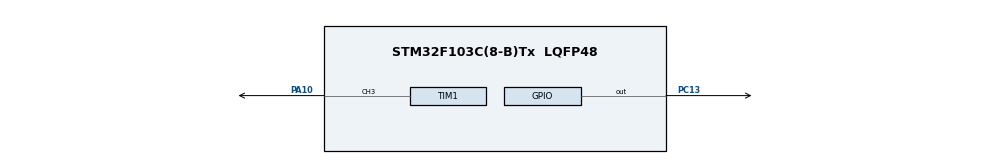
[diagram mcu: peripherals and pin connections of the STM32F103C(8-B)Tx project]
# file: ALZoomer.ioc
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Mcu.Family=STM32F1
Mcu.Name=STM32F103C(8-B)Tx
Mcu.Package=LQFP48
NVIC.PriorityGroup=NVIC_PRIORITYGROUP_4
PA10.Signal=S_TIM1_CH3
PA13.Mode=Serial_Wire
PA13.Signal=SYS_JTMS-SWDIO
PA14.Mode=Serial_Wire
PA14.Signal=SYS_JTCK-SWCLK
PC13-TAMPER-RTC.Signal=GPIO_Output
ProjectManager.HeapSize=0x200
ProjectManager.StackSize=0x400
ProjectManager.TargetToolchain=STM32CubeIDE
RCC.APB1Freq_Value=8000000
RCC.APB2Freq_Value=8000000
SH.S_TIM1_CH3.0=TIM1_CH3,PWM Generation3 CH3
TIM1.Channel-PWM\ Generation3\ CH3=TIM_CHANNEL_3
TIM1.Period=99
TIM1.Prescaler=39
TIM1.Pulse-PWM\ Generation3\ CH3=49
TIM1.RepetitionCounter=0
VP_TIM1_VS_ClockSourceINT.Mode=Internal
board=custom

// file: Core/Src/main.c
/* USER CODE BEGIN Header */
/**
  ******************************************************************************
  * @file           : main.c
  * @brief          : Main program body
  ******************************************************************************
  * @attention
  *
  * <h2><center>&copy; Copyright (c) 2021 STMicroelectronics.
  * All rights reserved.</center></h2>
  *
  * This software component is licensed by ST under BSD 3-Clause license,
  * the "License"; You may not use this file except in compliance with the
  * License. You may obtain a copy of the License at:
  *                        opensource.org/licenses/BSD-3-Clause
  *
  ******************************************************************************
  */
/* USER CODE END Header */

#include "main.h"

TIM_HandleTypeDef htim1;

void SystemClock_Config(void);
static void MX_GPIO_Init(void);
static void MX_TIM1_Init(void);
/* USER CODE BEGIN PFP */
void setPWM(uint16_t pwm_value);
/* USER CODE END PFP */

int main(void)
{

  /* MCU Configuration--------------------------------------------------------*/

  /* Reset of all peripherals, Initializes the Flash interface and the Systick. */
  HAL_Init();

  /* Configure the system clock */
  SystemClock_Config();

  /* Initialize all configured peripherals */
  MX_GPIO_Init();
  MX_TIM1_Init();

  /* Infinite loop */
  /* USER CODE BEGIN WHILE */
  while (1)
  {
//    setPWM(30);
    __HAL_TIM_SET_PRESCALER(&htim1, 39);
    HAL_TIM_PWM_Start(&htim1, TIM_CHANNEL_3);
    HAL_GPIO_WritePin(GPIOC, GPIO_PIN_13, GPIO_PIN_RESET);
    HAL_Delay(1000);
//    setPWM(0);
    HAL_TIM_PWM_Stop(&htim1, TIM_CHANNEL_3);
    HAL_GPIO_WritePin(GPIOC, GPIO_PIN_13, GPIO_PIN_SET);
    HAL_Delay(500);

    __HAL_TIM_SET_PRESCALER(&htim1, 29);
    HAL_TIM_PWM_Start(&htim1, TIM_CHANNEL_3);
    HAL_GPIO_WritePin(GPIOC, GPIO_PIN_13, GPIO_PIN_RESET);
    HAL_Delay(1000);
//    setPWM(0);
    HAL_TIM_PWM_Stop(&htim1, TIM_CHANNEL_3);
    HAL_GPIO_WritePin(GPIOC, GPIO_PIN_13, GPIO_PIN_SET);
    HAL_Delay(500);

    /* USER CODE END WHILE */

  }
}

void SystemClock_Config(void)
{
  RCC_OscInitTypeDef RCC_OscInitStruct = {0};
  RCC_ClkInitTypeDef RCC_ClkInitStruct = {0};

  /** Initializes the CPU, AHB and APB busses clocks
  */
  RCC_OscInitStruct.OscillatorType = RCC_OSCILLATORTYPE_HSI;
  RCC_OscInitStruct.HSIState = RCC_HSI_ON;
  RCC_OscInitStruct.HSICalibrationValue = RCC_HSICALIBRATION_DEFAULT;
  RCC_OscInitStruct.PLL.PLLState = RCC_PLL_NONE;
  if (HAL_RCC_OscConfig(&RCC_OscInitStruct) != HAL_OK)
  {
    Error_Handler();
  }
  /** Initializes the CPU, AHB and APB busses clocks
  */
  RCC_ClkInitStruct.ClockType = RCC_CLOCKTYPE_HCLK|RCC_CLOCKTYPE_SYSCLK
                              |RCC_CLOCKTYPE_PCLK1|RCC_CLOCKTYPE_PCLK2;
  RCC_ClkInitStruct.SYSCLKSource = RCC_SYSCLKSOURCE_HSI;
  RCC_ClkInitStruct.AHBCLKDivider = RCC_SYSCLK_DIV1;
  RCC_ClkInitStruct.APB1CLKDivider = RCC_HCLK_DIV1;
  RCC_ClkInitStruct.APB2CLKDivider = RCC_HCLK_DIV1;

  if (HAL_RCC_ClockConfig(&RCC_ClkInitStruct, FLASH_LATENCY_0) != HAL_OK)
  {
    Error_Handler();
  }
}

static void MX_TIM1_Init(void)
{

  TIM_ClockConfigTypeDef sClockSourceConfig = {0};
  TIM_MasterConfigTypeDef sMasterConfig = {0};
  TIM_OC_InitTypeDef sConfigOC = {0};
  TIM_BreakDeadTimeConfigTypeDef sBreakDeadTimeConfig = {0};

  htim1.Instance = TIM1;
  htim1.Init.Prescaler = 39;
  htim1.Init.CounterMode = TIM_COUNTERMODE_UP;
  htim1.Init.Period = 99;
  htim1.Init.ClockDivision = TIM_CLOCKDIVISION_DIV1;
  htim1.Init.RepetitionCounter = 0;
  htim1.Init.AutoReloadPreload = TIM_AUTORELOAD_PRELOAD_DISABLE;
  if (HAL_TIM_Base_Init(&htim1) != HAL_OK)
  {
    Error_Handler();
  }
  sClockSourceConfig.ClockSource = TIM_CLOCKSOURCE_INTERNAL;
  if (HAL_TIM_ConfigClockSource(&htim1, &sClockSourceConfig) != HAL_OK)
  {
    Error_Handler();
  }
  if (HAL_TIM_PWM_Init(&htim1) != HAL_OK)
  {
    Error_Handler();
  }
  sMasterConfig.MasterOutputTrigger = TIM_TRGO_RESET;
  sMasterConfig.MasterSlaveMode = TIM_MASTERSLAVEMODE_DISABLE;
  if (HAL_TIMEx_MasterConfigSynchronization(&htim1, &sMasterConfig) != HAL_OK)
  {
    Error_Handler();
  }
  sConfigOC.OCMode = TIM_OCMODE_PWM1;
  sConfigOC.Pulse = 49;
  sConfigOC.OCPolarity = TIM_OCPOLARITY_HIGH;
  sConfigOC.OCNPolarity = TIM_OCNPOLARITY_HIGH;
  sConfigOC.OCFastMode = TIM_OCFAST_DISABLE;
  sConfigOC.OCIdleState = TIM_OCIDLESTATE_RESET;
  sConfigOC.OCNIdleState = TIM_OCNIDLESTATE_RESET;
  if (HAL_TIM_PWM_ConfigChannel(&htim1, &sConfigOC, TIM_CHANNEL_3) != HAL_OK)
  {
    Error_Handler();
  }
  sBreakDeadTimeConfig.OffStateRunMode = TIM_OSSR_DISABLE;
  sBreakDeadTimeConfig.OffStateIDLEMode = TIM_OSSI_DISABLE;
  sBreakDeadTimeConfig.LockLevel = TIM_LOCKLEVEL_OFF;
  sBreakDeadTimeConfig.DeadTime = 0;
  sBreakDeadTimeConfig.BreakState = TIM_BREAK_DISABLE;
  sBreakDeadTimeConfig.BreakPolarity = TIM_BREAKPOLARITY_HIGH;
  sBreakDeadTimeConfig.AutomaticOutput = TIM_AUTOMATICOUTPUT_DISABLE;
  if (HAL_TIMEx_ConfigBreakDeadTime(&htim1, &sBreakDeadTimeConfig) != HAL_OK)
  {
    Error_Handler();
  }
  HAL_TIM_MspPostInit(&htim1);

}

static void MX_GPIO_Init(void)
{
  GPIO_InitTypeDef GPIO_InitStruct = {0};

  /* GPIO Ports Clock Enable */
  __HAL_RCC_GPIOC_CLK_ENABLE();
  __HAL_RCC_GPIOA_CLK_ENABLE();

  /*Configure GPIO pin Output Level */
  HAL_GPIO_WritePin(GPIOC, GPIO_PIN_13, GPIO_PIN_RESET);

  /*Configure GPIO pin : PC13 */
  GPIO_InitStruct.Pin = GPIO_PIN_13;
  GPIO_InitStruct.Mode = GPIO_MODE_OUTPUT_PP;
  GPIO_InitStruct.Pull = GPIO_NOPULL;
  GPIO_InitStruct.Speed = GPIO_SPEED_FREQ_LOW;
  HAL_GPIO_Init(GPIOC, &GPIO_InitStruct);

}

/* USER CODE BEGIN 4 */
void setPWM(uint16_t value)
{
    TIM_OC_InitTypeDef sConfigOC;

    sConfigOC.OCMode = TIM_OCMODE_PWM1;
    sConfigOC.Pulse = value;
    sConfigOC.OCPolarity = TIM_OCPOLARITY_HIGH;
    sConfigOC.OCFastMode = TIM_OCFAST_DISABLE;
    HAL_TIM_PWM_ConfigChannel(&htim1, &sConfigOC, TIM_CHANNEL_3); // таймер №1, канал №3
    HAL_TIM_PWM_Start(&htim1, TIM_CHANNEL_3);
}
/* USER CODE END 4 */

void Error_Handler(void)
{
}

/************************ (C) COPYRIGHT STMicroelectronics *****END OF FILE****/
